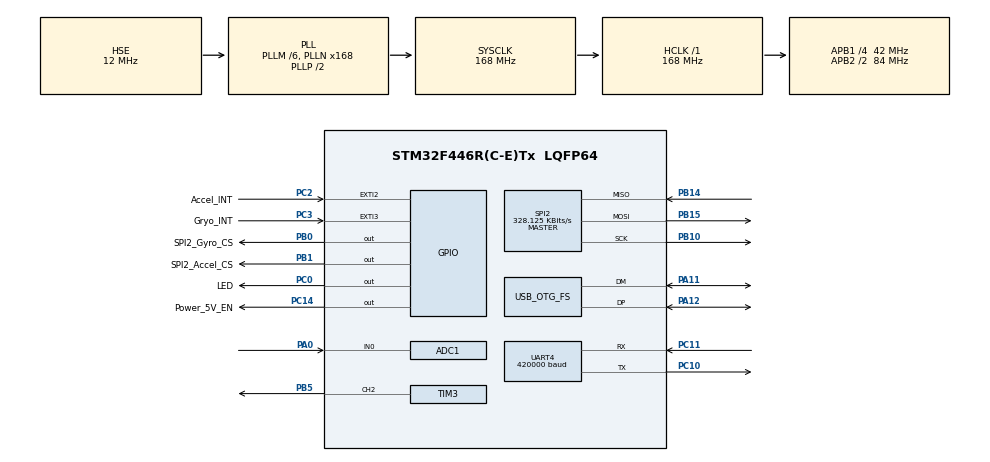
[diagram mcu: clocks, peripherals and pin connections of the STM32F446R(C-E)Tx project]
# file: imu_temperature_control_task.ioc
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ADC1.Channel-0\#ChannelRegularConversion=ADC_CHANNEL_0
ADC1.ContinuousConvMode=DISABLE
ADC1.NbrOfConversionFlag=1
ADC1.Rank-0\#ChannelRegularConversion=1
ADC1.SamplingTime-0\#ChannelRegularConversion=ADC_SAMPLETIME_28CYCLES
ADC1.ScanConvMode=DISABLE
ADC1.master=1
Dma.Request0=UART4_RX
Dma.Request1=UART4_TX
Dma.UART4_RX.0.Direction=DMA_PERIPH_TO_MEMORY
Dma.UART4_RX.0.FIFOMode=DMA_FIFOMODE_DISABLE
Dma.UART4_RX.0.Instance=DMA1_Stream2
Dma.UART4_RX.0.MemDataAlignment=DMA_MDATAALIGN_BYTE
Dma.UART4_RX.0.MemInc=DMA_MINC_ENABLE
Dma.UART4_RX.0.Mode=DMA_NORMAL
Dma.UART4_RX.0.PeriphDataAlignment=DMA_PDATAALIGN_BYTE
Dma.UART4_RX.0.PeriphInc=DMA_PINC_DISABLE
Dma.UART4_RX.0.Priority=DMA_PRIORITY_HIGH
Dma.UART4_TX.1.Direction=DMA_MEMORY_TO_PERIPH
Dma.UART4_TX.1.FIFOMode=DMA_FIFOMODE_DISABLE
Dma.UART4_TX.1.Instance=DMA1_Stream4
Dma.UART4_TX.1.MemDataAlignment=DMA_MDATAALIGN_BYTE
Dma.UART4_TX.1.MemInc=DMA_MINC_ENABLE
Dma.UART4_TX.1.Mode=DMA_NORMAL
Dma.UART4_TX.1.PeriphDataAlignment=DMA_PDATAALIGN_BYTE
Dma.UART4_TX.1.PeriphInc=DMA_PINC_DISABLE
Dma.UART4_TX.1.Priority=DMA_PRIORITY_LOW
FREERTOS.INCLUDE_xTaskGetCurrentTaskHandle=1
FREERTOS.INCLUDE_xTaskGetHandle=1
FREERTOS.Tasks01=TEMP_IMU,0,512,imu_temp_control_task,As weak,NULL,Dynamic,NULL,NULL;TELE_TASK,-3,128,tele_task,As weak,NULL,Dynamic,NULL,NULL;LED_TASK,-2,128,led_task,As weak,NULL,Dynamic,NULL,NULL
FREERTOS.configUSE_PREEMPTION=1
Mcu.Family=STM32F4
Mcu.Name=STM32F446R(C-E)Tx
Mcu.Package=LQFP64
NVIC.DMA1_Stream2_IRQn=true\:5\:0\:false\:false\:true\:false\:false\:true\:true
NVIC.DMA1_Stream4_IRQn=true\:5\:0\:false\:false\:true\:false\:false\:true\:true
NVIC.OTG_FS_IRQn=true\:5\:0\:false\:false\:true\:false\:false\:true\:true
NVIC.PriorityGroup=NVIC_PRIORITYGROUP_4
NVIC.TIM7_IRQn=true\:15\:0\:false\:false\:true\:false\:false\:true\:true
NVIC.TimeBase=TIM7_IRQn
NVIC.TimeBaseIP=TIM7
NVIC.UART4_IRQn=true\:5\:0\:false\:false\:true\:false\:true\:true\:true
PA0-WKUP.Signal=ADCx_IN0
PA11.Mode=Device_Only
PA11.Signal=USB_OTG_FS_DM
PA12.Mode=Device_Only
PA12.Signal=USB_OTG_FS_DP
PA13.Mode=Serial_Wire
PA13.Signal=SYS_JTMS-SWDIO
PA14.Mode=Serial_Wire
PA14.Signal=SYS_JTCK-SWCLK
PB0.GPIO_Label=SPI2_Gyro_CS
PB0.Signal=GPIO_Output
PB1.GPIO_Label=SPI2_Accel_CS
PB1.Signal=GPIO_Output
PB10.Mode=Full_Duplex_Master
PB10.Signal=SPI2_SCK
PB14.Mode=Full_Duplex_Master
PB14.Signal=SPI2_MISO
PB15.Mode=Full_Duplex_Master
PB15.Signal=SPI2_MOSI
PB5.GPIO_PuPd=GPIO_PULLDOWN
PB5.GPIO_Speed=GPIO_SPEED_FREQ_HIGH
PB5.Signal=S_TIM3_CH2
PC0.GPIO_Label=LED
PC0.GPIO_ModeDefaultOutputPP=GPIO_MODE_OUTPUT_PP
PC0.GPIO_PuPd=GPIO_NOPULL
PC0.GPIO_Speed=GPIO_SPEED_FREQ_LOW
PC0.PinState=GPIO_PIN_RESET
PC0.Signal=GPIO_Output
PC10.Mode=Asynchronous
PC10.Signal=UART4_TX
PC11.Mode=Asynchronous
PC11.Signal=UART4_RX
PC14-OSC32_IN.GPIO_Label=Power_5V_EN
PC14-OSC32_IN.GPIO_ModeDefaultOutputPP=GPIO_MODE_OUTPUT_PP
PC14-OSC32_IN.GPIO_PuPd=GPIO_PULLUP
PC14-OSC32_IN.PinState=GPIO_PIN_SET
PC14-OSC32_IN.Signal=GPIO_Output
PC2.GPIO_Label=Accel_INT
PC2.Signal=GPXTI2
PC3.GPIO_Label=Gryo_INT
PC3.GPIO_PuPd=GPIO_PULLUP
PC3.Signal=GPXTI3
PH0-OSC_IN.Mode=HSE-External-Oscillator
PH0-OSC_IN.Signal=RCC_OSC_IN
PH1-OSC_OUT.Mode=HSE-External-Oscillator
PH1-OSC_OUT.Signal=RCC_OSC_OUT
ProjectManager.HeapSize=0x400
ProjectManager.StackSize=0x800
ProjectManager.TargetToolchain=MDK-ARM V5.32
RCC.AHBFreq_Value=168000000
RCC.APB1CLKDivider=RCC_HCLK_DIV4
RCC.APB1Freq_Value=42000000
RCC.APB1TimFreq_Value=84000000
RCC.APB2CLKDivider=RCC_HCLK_DIV2
RCC.APB2Freq_Value=84000000
RCC.APB2TimFreq_Value=168000000
RCC.CortexFreq_Value=168000000
RCC.HCLKFreq_Value=168000000
RCC.HSE_VALUE=12000000
RCC.PLLM=6
RCC.PLLN=168
RCC.PLLQ=7
RCC.PLLSAIM=6
RCC.PLLSAIN=96
RCC.PLLSAIP=RCC_PLLSAIP_DIV4
RCC.PLLSourceVirtual=RCC_PLLSOURCE_HSE
RCC.SYSCLKFreq_VALUE=168000000
RCC.SYSCLKSource=RCC_SYSCLKSOURCE_PLLCLK
RCC.USBFreq_Value=48000000
RCC.VCOOutputFreq_Value=336000000
SH.ADCx_IN0.0=ADC1_IN0,IN0
SH.S_TIM3_CH2.0=TIM3_CH2,PWM Generation2 CH2
SPI2.BaudRatePrescaler=SPI_BAUDRATEPRESCALER_128
SPI2.CLKPhase=SPI_PHASE_2EDGE
SPI2.CLKPolarity=SPI_POLARITY_HIGH
SPI2.CalculateBaudRate=328.125 KBits/s
SPI2.Direction=SPI_DIRECTION_2LINES
SPI2.Mode=SPI_MODE_MASTER
SPI2.VirtualType=VM_MASTER
TIM3.Channel-PWM\ Generation2\ CH2=TIM_CHANNEL_2
TIM3.Period=4999
UART4.BaudRate=420000
UART4.VirtualMode=Asynchronous
USB_DEVICE.CLASS_NAME_FS=CDC
USB_DEVICE.VirtualMode-CDC_FS=Cdc
USB_DEVICE.VirtualModeFS=Cdc_FS
USB_OTG_FS.VirtualMode=Device_Only
VP_FREERTOS_VS_CMSIS_V1.Mode=CMSIS_V1
VP_SYS_VS_tim7.Mode=TIM7
VP_USB_DEVICE_VS_USB_DEVICE_CDC_FS.Mode=CDC_FS
board=custom

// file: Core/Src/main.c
/* USER CODE BEGIN Header */
/**
  ******************************************************************************
  * @file           : main.c
  * @brief          : Main program body
  ******************************************************************************
  * @attention
  *
  * <h2><center>&copy; Copyright (c) 2023 STMicroelectronics.
  * All rights reserved.</center></h2>
  *
  * This software component is licensed by ST under Ultimate Liberty license
  * SLA0044, the "License"; You may not use this file except in compliance with
  * the License. You may obtain a copy of the License at:
  *                             www.st.com/SLA0044
  *
  ******************************************************************************
  */
/* USER CODE END Header */
#include "main.h"
#include "cmsis_os.h"
#include "adc.h"
#include "dma.h"
#include "spi.h"
#include "tim.h"
#include "usart.h"
#include "usb_device.h"
#include "gpio.h"

void SystemClock_Config(void);
void MX_FREERTOS_Init(void);

int main(void)
{

  /* MCU Configuration--------------------------------------------------------*/

  /* Reset of all peripherals, Initializes the Flash interface and the Systick. */
  HAL_Init();

  /* Configure the system clock */
  SystemClock_Config();

  /* Initialize all configured peripherals */
  MX_GPIO_Init();
  MX_DMA_Init();
  MX_SPI2_Init();
  MX_TIM3_Init();
  MX_UART4_Init();
  MX_ADC1_Init();
  /* USER CODE BEGIN 2 */
  crsf_init();

  HAL_ADC_Start(&hadc1);
  HAL_ADC_PollForConversion(&hadc1, HAL_MAX_DELAY);
  /* USER CODE END 2 */

  /* Call init function for freertos objects (in cmsis_os2.c) */
  MX_FREERTOS_Init();

  /* Start scheduler */
  osKernelStart();

  /* We should never get here as control is now taken by the scheduler */

  /* Infinite loop */
  while (1)
  {

    /* USER CODE BEGIN 3 */
      //BMI088_read(gyro, accel, &temp);
     // HAL_Delay(10);
  }
  /* USER CODE END 3 */
}

void SystemClock_Config(void)
{
  RCC_OscInitTypeDef RCC_OscInitStruct = {0};
  RCC_ClkInitTypeDef RCC_ClkInitStruct = {0};

  /** Configure the main internal regulator output voltage
  */
  __HAL_RCC_PWR_CLK_ENABLE();
  __HAL_PWR_VOLTAGESCALING_CONFIG(PWR_REGULATOR_VOLTAGE_SCALE1);

  /** Initializes the RCC Oscillators according to the specified parameters
  * in the RCC_OscInitTypeDef structure.
  */
  RCC_OscInitStruct.OscillatorType = RCC_OSCILLATORTYPE_HSE;
  RCC_OscInitStruct.HSEState = RCC_HSE_ON;
  RCC_OscInitStruct.PLL.PLLState = RCC_PLL_ON;
  RCC_OscInitStruct.PLL.PLLSource = RCC_PLLSOURCE_HSE;
  RCC_OscInitStruct.PLL.PLLM = 6;
  RCC_OscInitStruct.PLL.PLLN = 168;
  RCC_OscInitStruct.PLL.PLLP = RCC_PLLP_DIV2;
  RCC_OscInitStruct.PLL.PLLQ = 7;
  RCC_OscInitStruct.PLL.PLLR = 2;
  if (HAL_RCC_OscConfig(&RCC_OscInitStruct) != HAL_OK)
  {
    Error_Handler();
  }

  /** Initializes the CPU, AHB and APB buses clocks
  */
  RCC_ClkInitStruct.ClockType = RCC_CLOCKTYPE_HCLK|RCC_CLOCKTYPE_SYSCLK
                              |RCC_CLOCKTYPE_PCLK1|RCC_CLOCKTYPE_PCLK2;
  RCC_ClkInitStruct.SYSCLKSource = RCC_SYSCLKSOURCE_PLLCLK;
  RCC_ClkInitStruct.AHBCLKDivider = RCC_SYSCLK_DIV1;
  RCC_ClkInitStruct.APB1CLKDivider = RCC_HCLK_DIV4;
  RCC_ClkInitStruct.APB2CLKDivider = RCC_HCLK_DIV2;

  if (HAL_RCC_ClockConfig(&RCC_ClkInitStruct, FLASH_LATENCY_5) != HAL_OK)
  {
    Error_Handler();
  }
}

void HAL_TIM_PeriodElapsedCallback(TIM_HandleTypeDef *htim)
{
  if (htim->Instance == TIM7) {
    HAL_IncTick();
  }
}

void Error_Handler(void)
{
}

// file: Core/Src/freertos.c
/* USER CODE BEGIN Header */
/**
  ******************************************************************************
  * File Name          : freertos.c
  * Description        : Code for freertos applications
  ******************************************************************************
  * @attention
  *
  * <h2><center>&copy; Copyright (c) 2023 STMicroelectronics.
  * All rights reserved.</center></h2>
  *
  * This software component is licensed by ST under Ultimate Liberty license
  * SLA0044, the "License"; You may not use this file except in compliance with
  * the License. You may obtain a copy of the License at:
  *                             www.st.com/SLA0044
  *
  ******************************************************************************
  */
/* USER CODE END Header */

#include "FreeRTOS.h"
#include "task.h"
#include "main.h"
#include "cmsis_os.h"

osThreadId TEMP_IMUHandle;
osThreadId TELE_TASKHandle;
osThreadId LED_TASKHandle;

/* USER CODE BEGIN FunctionPrototypes */
osThreadId LEDHandle;
/* USER CODE END FunctionPrototypes */

void imu_temp_control_task(void const * argument);
void tele_task(void const * argument);
void led_task(void const * argument);

extern void MX_USB_DEVICE_Init(void);
void MX_FREERTOS_Init(void); /* (MISRA C 2004 rule 8.1) */

/* GetIdleTaskMemory prototype (linked to static allocation support) */
void vApplicationGetIdleTaskMemory( StaticTask_t **ppxIdleTaskTCBBuffer, StackType_t **ppxIdleTaskStackBuffer, uint32_t *pulIdleTaskStackSize );

/* USER CODE BEGIN GET_IDLE_TASK_MEMORY */
static StaticTask_t xIdleTaskTCBBuffer;
static StackType_t xIdleStack[configMINIMAL_STACK_SIZE];

void vApplicationGetIdleTaskMemory( StaticTask_t **ppxIdleTaskTCBBuffer, StackType_t **ppxIdleTaskStackBuffer, uint32_t *pulIdleTaskStackSize )
{
  *ppxIdleTaskTCBBuffer = &xIdleTaskTCBBuffer;
  *ppxIdleTaskStackBuffer = &xIdleStack[0];
  *pulIdleTaskStackSize = configMINIMAL_STACK_SIZE;
  /* place for user code */
}
/* USER CODE END GET_IDLE_TASK_MEMORY */

void MX_FREERTOS_Init(void) {

  /* Create the thread(s) */
  /* definition and creation of TEMP_IMU */
  osThreadDef(TEMP_IMU, imu_temp_control_task, osPriorityNormal, 0, 512);
  TEMP_IMUHandle = osThreadCreate(osThread(TEMP_IMU), NULL);

  /* definition and creation of TELE_TASK */
  osThreadDef(TELE_TASK, tele_task, osPriorityIdle, 0, 128);
  TELE_TASKHandle = osThreadCreate(osThread(TELE_TASK), NULL);

  /* definition and creation of LED_TASK */
  osThreadDef(LED_TASK, led_task, osPriorityLow, 0, 128);
  LED_TASKHandle = osThreadCreate(osThread(LED_TASK), NULL);

}

__weak void imu_temp_control_task(void const * argument)
{
  /* init code for USB_DEVICE */
  MX_USB_DEVICE_Init();
  for(;;)
  {
    osDelay(1);
  }
}

__weak void tele_task(void const * argument)
{
  for(;;)
  {
    osDelay(1);
  }
}

__weak void led_task(void const * argument)
{
  for(;;)
  {
    osDelay(1);
  }
}
